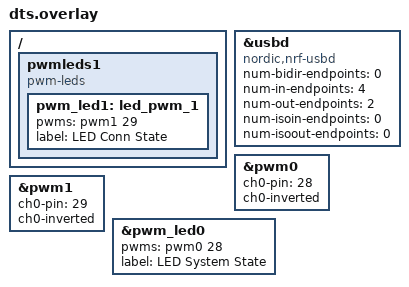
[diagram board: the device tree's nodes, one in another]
/ {
	pwmleds1 {
		compatible = "pwm-leds";
		status = "okay";

		pwm_led1: led_pwm_1 {
			status = "okay";
			pwms = <&pwm1 29>;
			label = "LED Conn State";
		};
	};
};

&usbd {
	compatible = "nordic,nrf-usbd";
	status = "okay";
	num-bidir-endpoints = <0>;
	num-in-endpoints = <4>;
	num-out-endpoints = <2>;
	num-isoin-endpoints = <0>;
	num-isoout-endpoints = <0>;
};

&pwm0 {
	status = "okay";
	ch0-pin = <28>;
	ch0-inverted;
};

&pwm1 {
	status = "okay";
	ch0-pin = <29>;
	ch0-inverted;
};

&pwm_led0 {
	status = "okay";
	pwms = <&pwm0 28>;
	label = "LED System State";
};
